VERSION ""

NS_ :

BS_:

BU_: XXX

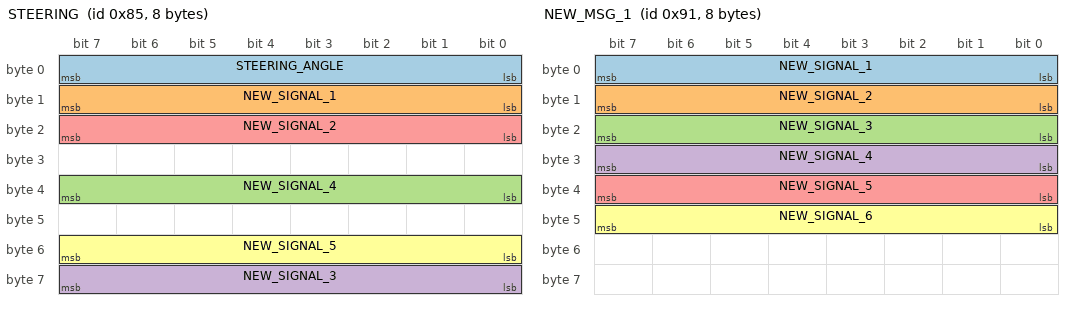
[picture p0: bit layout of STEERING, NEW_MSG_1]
BO_ 133 STEERING: 8 XXX
 SG_ STEERING_ANGLE : 7|8@0+ (1,0) [0|255] "" XXX
 SG_ NEW_SIGNAL_1 : 15|8@0+ (1,0) [0|255] "" XXX
 SG_ NEW_SIGNAL_4 : 39|8@0+ (1,0) [0|255] "" XXX
 SG_ NEW_SIGNAL_3 : 56|8@1+ (1,0) [0|255] "" XXX
 SG_ NEW_SIGNAL_2 : 23|8@0+ (1,0) [0|255] "" XXX
 SG_ NEW_SIGNAL_5 : 55|8@0+ (1,0) [0|255] "" XXX

BO_ 145 NEW_MSG_1: 8 XXX
 SG_ NEW_SIGNAL_1 : 0|8@1+ (1,0) [0|255] "" XXX
 SG_ NEW_SIGNAL_2 : 15|8@0+ (1,0) [0|255] "" XXX
 SG_ NEW_SIGNAL_3 : 23|8@0+ (1,0) [0|255] "" XXX
 SG_ NEW_SIGNAL_4 : 31|8@0+ (1,0) [0|255] "" XXX
 SG_ NEW_SIGNAL_5 : 39|8@0+ (1,0) [0|255] "" XXX
 SG_ NEW_SIGNAL_6 : 47|8@0+ (1,0) [0|255] "" XXX

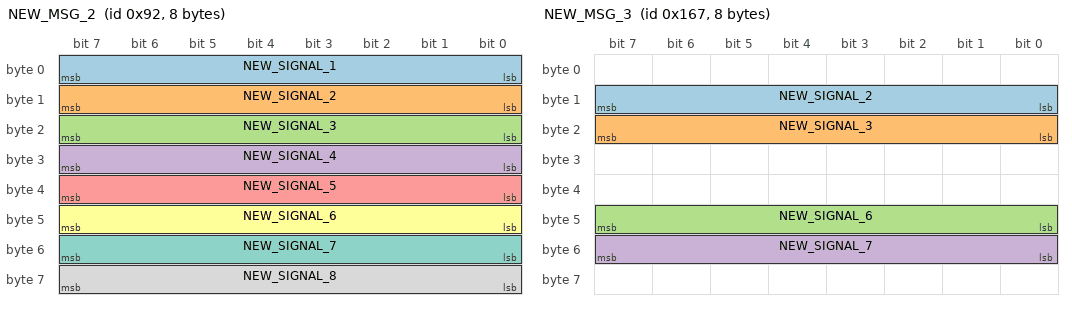
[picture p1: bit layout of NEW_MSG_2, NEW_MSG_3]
BO_ 146 NEW_MSG_2: 8 XXX
 SG_ NEW_SIGNAL_1 : 7|8@0+ (1,0) [0|255] "" XXX
 SG_ NEW_SIGNAL_2 : 15|8@0+ (1,0) [0|255] "" XXX
 SG_ NEW_SIGNAL_3 : 23|8@0+ (1,0) [0|255] "" XXX
 SG_ NEW_SIGNAL_4 : 31|8@0+ (1,0) [0|255] "" XXX
 SG_ NEW_SIGNAL_5 : 39|8@0+ (1,0) [0|255] "" XXX
 SG_ NEW_SIGNAL_6 : 47|8@0+ (1,0) [0|255] "" XXX
 SG_ NEW_SIGNAL_7 : 55|8@0+ (1,0) [0|255] "" XXX
 SG_ NEW_SIGNAL_8 : 63|8@0+ (1,0) [0|255] "" XXX

BO_ 359 NEW_MSG_3: 8 XXX
 SG_ NEW_SIGNAL_2 : 15|8@0+ (1,0) [0|255] "" XXX
 SG_ NEW_SIGNAL_3 : 23|8@0+ (1,0) [0|255] "" XXX
 SG_ NEW_SIGNAL_6 : 47|8@0+ (1,0) [0|255] "" XXX
 SG_ NEW_SIGNAL_7 : 55|8@0+ (1,0) [0|255] "" XXX

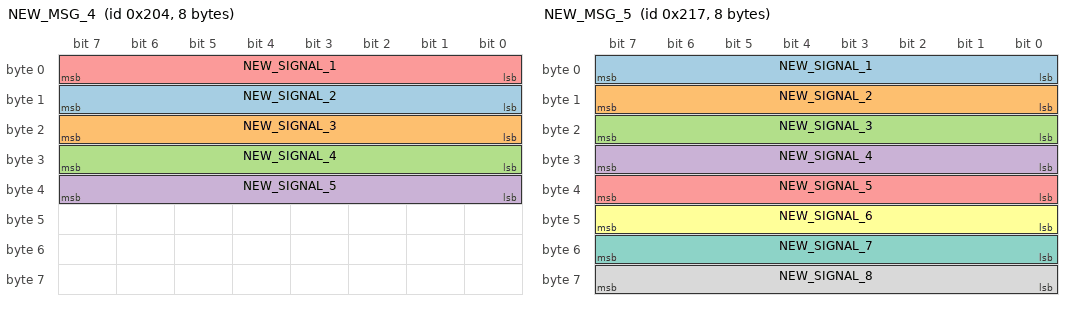
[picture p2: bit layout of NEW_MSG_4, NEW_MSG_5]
BO_ 516 NEW_MSG_4: 8 XXX
 SG_ NEW_SIGNAL_2 : 15|8@0+ (1,0) [0|255] "" XXX
 SG_ NEW_SIGNAL_3 : 23|8@0+ (1,0) [0|255] "" XXX
 SG_ NEW_SIGNAL_4 : 31|8@0+ (1,0) [0|255] "" XXX
 SG_ NEW_SIGNAL_5 : 39|8@0+ (1,0) [0|255] "" XXX
 SG_ NEW_SIGNAL_1 : 7|8@0+ (1,0) [0|255] "" XXX

BO_ 535 NEW_MSG_5: 8 XXX
 SG_ NEW_SIGNAL_1 : 7|8@0+ (1,0) [0|255] "" XXX
 SG_ NEW_SIGNAL_2 : 15|8@0+ (1,0) [0|255] "" XXX
 SG_ NEW_SIGNAL_3 : 23|8@0+ (1,0) [0|255] "" XXX
 SG_ NEW_SIGNAL_4 : 31|8@0+ (1,0) [0|255] "" XXX
 SG_ NEW_SIGNAL_5 : 39|8@0+ (1,0) [0|255] "" XXX
 SG_ NEW_SIGNAL_6 : 47|8@0+ (1,0) [0|255] "" XXX
 SG_ NEW_SIGNAL_7 : 55|8@0+ (1,0) [0|255] "" XXX
 SG_ NEW_SIGNAL_8 : 63|8@0+ (1,0) [0|255] "" XXX
